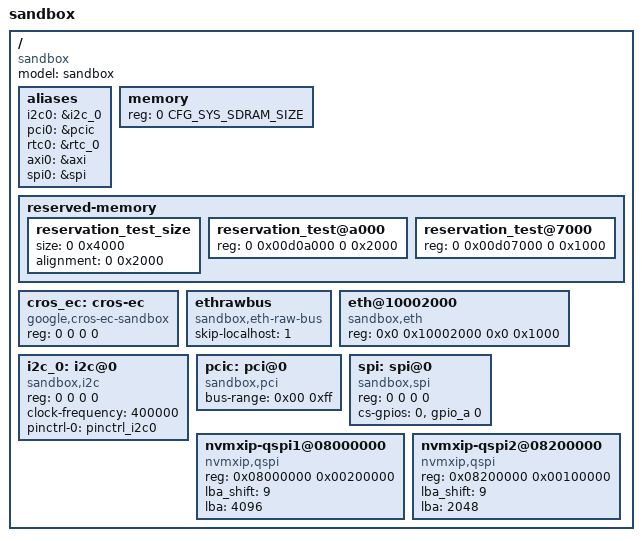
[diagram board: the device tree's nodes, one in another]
// SPDX-License-Identifier: GPL-2.0+
/*
 *  Main sandbox64 devicetree
 */
/dts-v1/;

#include <config.h>

/ {
	#address-cells = <2>;
	#size-cells = <2>;
	model = "sandbox";
	compatible = "sandbox";

	aliases {
		i2c0 = &i2c_0;
		pci0 = &pcic;
		rtc0 = &rtc_0;
		axi0 = &axi;
		spi0 = &spi;
	};

	memory {
		reg = /bits/ 64 <0 CFG_SYS_SDRAM_SIZE>;
	};

	reserved-memory {
		#address-cells = <2>;
		#size-cells = <2>;
		ranges;

		reservation_test_size {
			size = <0 0x4000>;
			alignment = <0 0x2000>;
		};

		reservation_test@a000 {
			reg = <0 0x00d0a000 0 0x2000>;
		};

		reservation_test@7000 {
			reg = <0 0x00d07000 0 0x1000>;
		};
	};

	/* ... */
	cros_ec: cros-ec {
		reg = <0 0 0 0>;
		bootph-all;
		compatible = "google,cros-ec-sandbox";
	};

	ethrawbus {
		compatible = "sandbox,eth-raw-bus";
		skip-localhost = <1>;
	};

	eth@10002000 {
		compatible = "sandbox,eth";
		reg = <0x0 0x10002000 0x0 0x1000>;
	};

	i2c_0: i2c@0 {
		#address-cells = <1>;
		#size-cells = <0>;
		reg = <0 0 0 0>;
		compatible = "sandbox,i2c";
		clock-frequency = <400000>;
		pinctrl-names = "default";
		pinctrl-0 = <&pinctrl_i2c0>;
	};

	pcic: pci@0 {
		compatible = "sandbox,pci";
		device_type = "pci";
		bus-range = <0x00 0xff>;
		#address-cells = <3>;
		#size-cells = <2>;
		ranges = <0x02000000 0 0x10000000 0 0x10000000 0 0x2000
				0x01000000 0 0x20000000 0 0x20000000 0 0x2000>;
	};

	spi: spi@0 {
		bootph-all;
		#address-cells = <1>;
		#size-cells = <0>;
		reg = <0 0 0 0>;
		compatible = "sandbox,spi";
		cs-gpios = <0>, <&gpio_a 0>;
	};

	nvmxip-qspi1@08000000 {
		compatible = "nvmxip,qspi";
		reg = /bits/ 64 <0x08000000 0x00200000>;
		lba_shift = <9>;
		lba = <4096>;
	};

	nvmxip-qspi2@08200000 {
		compatible = "nvmxip,qspi";
		reg = /bits/ 64 <0x08200000 0x00100000>;
		lba_shift = <9>;
		lba = <2048>;
	};
};

#include "sandbox.dtsi"
#include "cros-ec-keyboard.dtsi"
#include "sandbox_pmic.dtsi"
